# STM32L151 register map
File version: 1.6
CPU: CM3 r1p1, little endian, no MPU, no FPU, 4 interrupt priority bits
Registers are 32-bit, read-write, reset 0x0 unless marked. A register's access mark holds for its fields unless they carry their own. Offsets are from the block's base; [hi:lo] are bit positions; {n}, {i} and the like mark numbered series; 'fields as' and 'values as' point back to an identical list.

## EXTI — External interrupt/event controller
Base 0x40010400
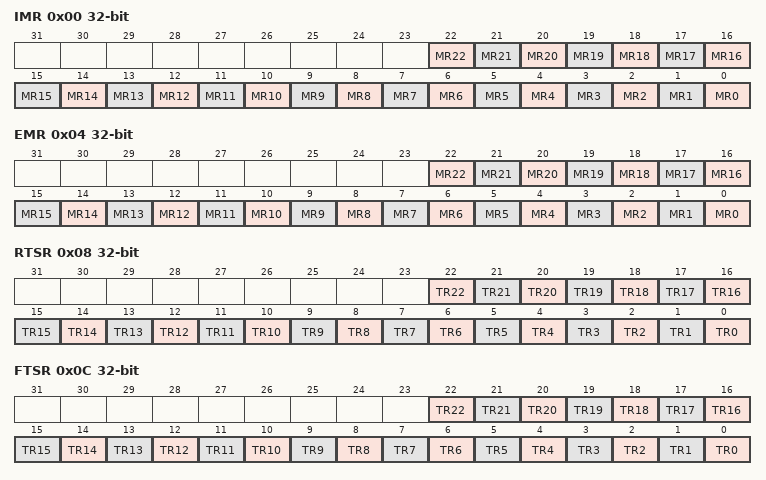
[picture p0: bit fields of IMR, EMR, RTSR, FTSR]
0x00 IMR
  [n] MR{n} (n=0..22) — Interrupt mask on line x
    0=Masked (Interrupt request line is masked); 1=Unmasked (Interrupt request line is unmasked)
0x04 EMR
  [n] MR{n} (n=0..22) — Event mask on line x
    0=Masked (Event request line is masked); 1=Unmasked (Event request line is unmasked)
0x08 RTSR
  [n] TR{n} (n=0..22) — Rising edge trigger event configuration bit of line x
    0=Disabled (Rising edge trigger is disabled); 1=Enabled (Rising edge trigger is enabled)
0x0C FTSR
  [n] TR{n} (n=0..22) — Falling edge trigger event configuration bit of line x
    0=Disabled (Falling edge trigger is disabled); 1=Enabled (Falling edge trigger is enabled)
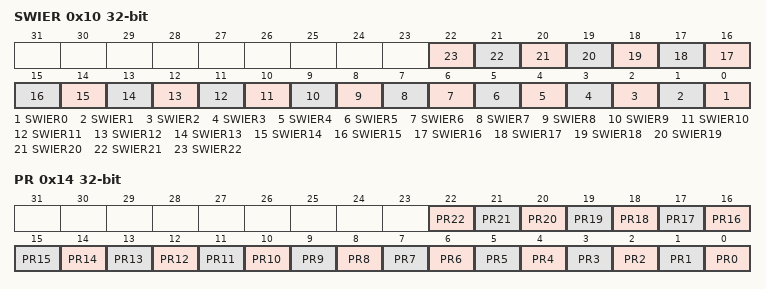
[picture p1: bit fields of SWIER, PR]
0x10 SWIER
  [n] SWIER{n} (n=0..22) — Software Interrupt on line {n}
    on write: 1=Pend (Generates an interrupt request)
0x14 PR
  [n] PR{n} (n=0..22) write-1-clears — Pending bit
    on read: 0=NotPending (No trigger request occurred); 1=Pending (Selected trigger request occurred) | on write: 1=Clears pending bit

## Flash
Base 0x40023C00
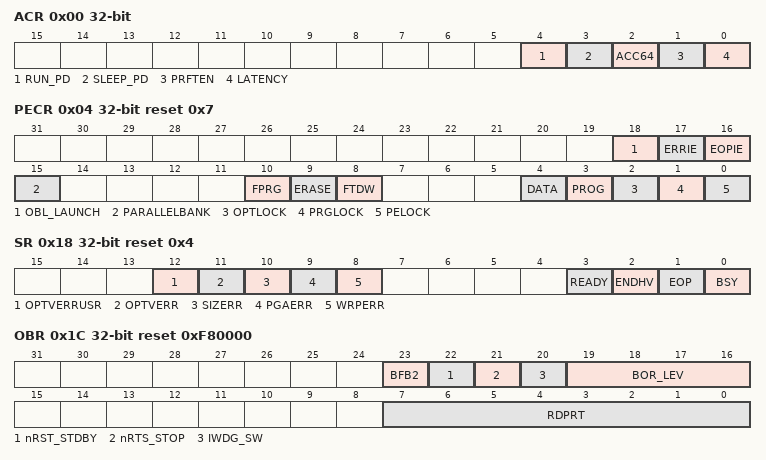
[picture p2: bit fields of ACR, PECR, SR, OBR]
0x00 ACR — Access control register
  [4] RUN_PD — Flash mode during Run
  [3] SLEEP_PD — Flash mode during Sleep
  [2] ACC64 — 64-bit access
  [1] PRFTEN — Prefetch enable
  [0] LATENCY
0x04 PECR reset 0x7 — Program/erase control register
  [18] OBL_LAUNCH — Launch the option byte loading
  [17] ERRIE — Error interrupt enable
  [16] EOPIE — End of programming interrupt enable
  [15] PARALLELBANK — Parallel bank mode
  [10] FPRG — Half Page/Double Word programming mode
  [9] ERASE — Page or Double Word erase mode
  [8] FTDW — Fixed time data write for Byte, Half Word and Word programming
  [4] DATA — Data EEPROM selection
  [3] PROG — Program memory selection
  [2] OPTLOCK — Option bytes block lock
  [1] PRGLOCK — Program memory lock
  [0] PELOCK — FLASH_PECR and data EEPROM lock
0x08 PDKEYR wo — Power down key register
  [31:0] PDKEYR — RUN_PD in FLASH_ACR key
0x0C PEKEYR wo — Program/erase key register
  [31:0] PEKEYR — FLASH_PEC and data EEPROM key
0x10 PRGKEYR wo — Program memory key register
  [31:0] PRGKEYR — Program memory key
0x14 OPTKEYR wo — Option byte key register
  [31:0] OPTKEYR — Option byte key
0x18 SR access per field reset 0x4 — Status register
  [12] OPTVERRUSR rw — Option UserValidity Error
  [11] OPTVERR rw — Option validity error
  [10] SIZERR rw — Size error
  [9] PGAERR rw — Programming alignment error
  [8] WRPERR rw — Write protected error
  [3] READY ro — Flash memory module ready after low power mode
  [2] ENDHV ro — End of high voltage
  [1] EOP ro — End of operation
  [0] BSY ro — Write/erase operations in progress
0x1C OBR ro reset 0xF80000 — Option byte register
  [23] BFB2 — Boot From Bank 2
  [22] nRST_STDBY
  [21] nRTS_STOP
  [20] IWDG_SW
  [19:16] BOR_LEV
  [7:0] RDPRT — Read protection
0x20 WRPR1 — Write protection register
  [31:0] WRP1 — Write protection
0x80 WRPR2 — Write protection register
  [31:0] WRP2
0x84 WRPR3 — Write protection register
  [31:0] WRP3

## FSMC — Flexible static memory controller
Base 0xA0000000
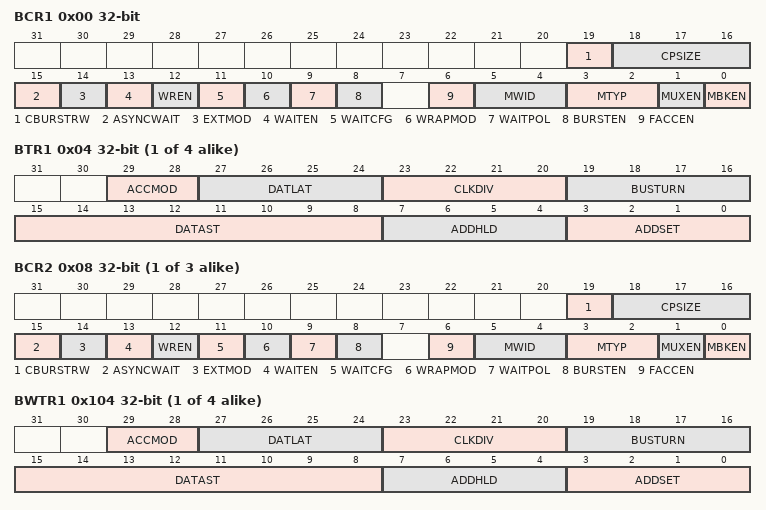
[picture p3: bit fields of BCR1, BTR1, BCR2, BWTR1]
0x00 BCR1
  [19] CBURSTRW
    0=Disabled (Write operations are always performed in asynchronous mode); 1=Enabled (Write operations are performed in synchronous mode)
  [18:16] CPSIZE — CRAM page size
    0=No burst split when crossing page boundary; 1=Bytes128 (128 bytes CRAM page size); 2=Bytes256 (256 bytes CRAM page size); 3=Bytes512 (512 bytes CRAM page size); 4=Bytes1024 (1024 bytes CRAM page size)
  [15] ASYNCWAIT
    0=Disabled (Wait signal not used in asynchronous mode); 1=Enabled (Wait signal used even in asynchronous mode)
  [14] EXTMOD
    0=Disabled (Values inside the FMC_BWTR are not taken into account); 1=Enabled (Values inside the FMC_BWTR are taken into account)
  [13] WAITEN
    0=Disabled (Values inside the FMC_BWTR are taken into account); 1=Enabled (NWAIT signal enabled)
  [12] WREN
    0=Disabled (Write operations disabled for the bank by the FMC); 1=Enabled (Write operations enabled for the bank by the FMC)
  [11] WAITCFG
    0=BeforeWaitState (NWAIT signal is active one data cycle before wait state); 1=DuringWaitState (NWAIT signal is active during wait state)
  [10] WRAPMOD
    0=Disabled (Direct wrapped burst is not enabled); 1=Enabled (Direct wrapped burst is enabled)
  [9] WAITPOL
    0=ActiveLow (NWAIT active low); 1=ActiveHigh (NWAIT active high)
  [8] BURSTEN
    0=Disabled (Burst mode disabled); 1=Enabled (Burst mode enabled)
  [6] FACCEN
    0=Disabled (Corresponding NOR Flash memory access is disabled); 1=Enabled (Corresponding NOR Flash memory access is enabled)
  [5:4] MWID
    0=Bits8 (Memory data bus width 8 bits); 1=Bits16 (Memory data bus width 16 bits); 2=Bits32 (Memory data bus width 32 bits)
  [3:2] MTYP
    0=SRAM (SRAM memory type); 1=PSRAM (PSRAM (CRAM) memory type); 2=Flash (NOR Flash/OneNAND Flash)
  [1] MUXEN
    0=Disabled (Address/Data non-multiplexed); 1=Enabled (Address/Data multiplexed on databus)
  [0] MBKEN
    0=Disabled (Corresponding memory bank is disabled); 1=Enabled (Corresponding memory bank is enabled)
0x04 BTR{i} (i=1..4; step 0x8) — BTR{i}
  [29:28] ACCMOD
    0=A (Access mode A); 1=B (Access mode B); 2=C (Access mode C); 3=D (Access mode D)
  [27:24] DATLAT
  [23:20] CLKDIV range 1..15
  [19:16] BUSTURN
  [15:8] DATAST range 1..255
  [7:4] ADDHLD range 1..15
  [3:0] ADDSET
0x08 BCR{i} (i=2..4; step 0x8) — BCR{i}
  fields as BCR1
{0xFC+8i} BWTR{i} (i=1..4) — BWTR{i}
  [29:28] ACCMOD
    values as BTR{i}.ACCMOD
  [27:24] DATLAT
  [23:20] CLKDIV
  [19:16] BUSTURN — Bus turnaround phase duration
  [15:8] DATAST range 1..255
  [7:4] ADDHLD range 1..15
  [3:0] ADDSET
